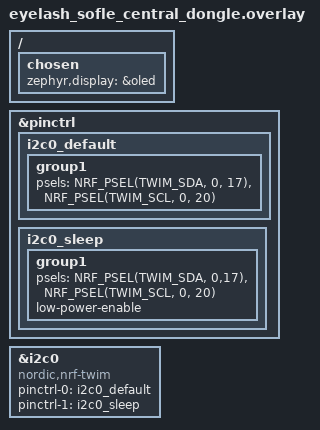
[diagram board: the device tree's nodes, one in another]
/*
*
* Copyright (c) 2021 Darryl deHaan
* SPDX-License-Identifier: MIT
*
*/

#include "eyelash_sofle.dtsi"

/{
    chosen {
        
        zephyr,display = &oled;
    };
   
};

&pinctrl {
    i2c0_default: i2c0_default {
        group1 {
            psels = <NRF_PSEL(TWIM_SDA, 0, 17)>,
                <NRF_PSEL(TWIM_SCL, 0, 20)>;
        };
    };

    i2c0_sleep: i2c0_sleep {
        group1 {
            psels = <NRF_PSEL(TWIM_SDA, 0,17)>,
                <NRF_PSEL(TWIM_SCL, 0, 20)>;
            low-power-enable;
        };
    };	
}; 

&i2c0 {
    status = "okay";
    compatible = "nordic,nrf-twim";
    pinctrl-0 = <&i2c0_default>;
    pinctrl-1 = <&i2c0_sleep>;
    pinctrl-names = "default", "sleep";

};


